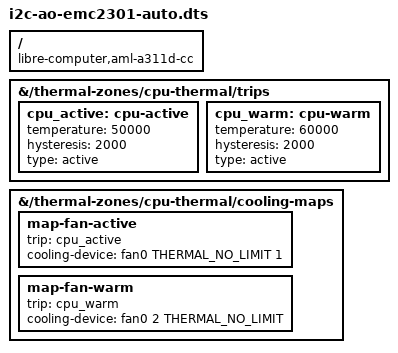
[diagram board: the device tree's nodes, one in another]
// SPDX-License-Identifier: (GPL-2.0-or-later OR MIT)
/*
 * Copyright (C) 2025 Da Xue
 * Author: Da Xue <da@libre.computer>
 */
/*
 * Summary: Temperature-based fan control for EMC2301 on I2C_AO (LoveRPi PoE+ HAT)
 *
 * Pins (Header.Pin  Name  Pad  Ref — cross-ref gpio.map):
 *   7J1.3    GPIOAO_3      BF13    I2C_AO_M0_SDA
 *   7J1.5    GPIOAO_2      AU40    I2C_AO_M0_SCL
 *
 * Requires: i2c-ao-emc2301
 *
 * Resource-requires: emc2301-fan
 * Notes:
 *   Requires i2c-ao-emc2301 (device + fan0). Maps cpu-thermal trips to fan0.
 */

/dts-v1/;
/plugin/;

#include <dt-bindings/thermal/thermal.h>

/ {
	compatible = "libre-computer,aml-a311d-cc",
		     "libretech,aml-a311d-cc",
		     "libre-computer,aml-a311d-cc-v01",
		     "libretech,aml-a311d-cc-v01",
		     "libre-computer,aml-s905d3-cc",
		     "libretech,aml-s905d3-cc",
		     "libre-computer,aml-s905d3-cc-v01",
		     "libretech,aml-s905d3-cc-v01",
		     "amlogic,a311d",
		     "amlogic,g12b",
		     "amlogic,s905d3",
		     "amlogic,sm1";
fragment@0 {
		target-path = "/thermal-zones/cpu-thermal/trips";

		__overlay__ {
			cpu_active: cpu-active {
				temperature = <50000>;
				hysteresis = <2000>;
				type = "active";
			};
			cpu_warm: cpu-warm {
				temperature = <60000>;
				hysteresis = <2000>;
				type = "active";
			};
		};
	};

	fragment@1 {
		target-path = "/thermal-zones/cpu-thermal/cooling-maps";

		__overlay__ {
			/*
			 * Fan maps get their own names: a "mapN" the base DTB also
			 * has is MERGED, replacing the base's cooling-device and trip
			 * (on S905X that was the passive-trip map2, on A311D the
			 * CPUs' hot-trip map1).
			 */
			map-fan-active {
				trip = <&cpu_active>;
				cooling-device = <&fan0 THERMAL_NO_LIMIT 1>;
			};
			map-fan-warm {
				trip = <&cpu_warm>;
				cooling-device = <&fan0 2 THERMAL_NO_LIMIT>;
			};
		};
	};
};
